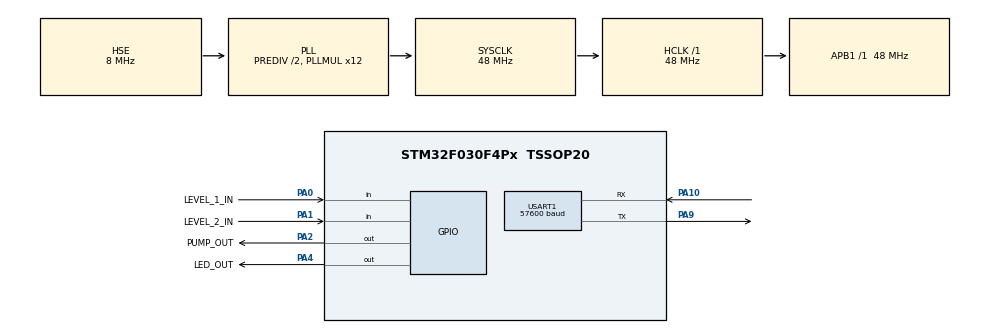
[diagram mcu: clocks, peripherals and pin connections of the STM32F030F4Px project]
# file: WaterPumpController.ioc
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Mcu.Family=STM32F0
Mcu.Name=STM32F030F4Px
Mcu.Package=TSSOP20
NVIC.TIM14_IRQn=true\:0\:0\:false\:false\:true\:true\:true
PA0.GPIO_Label=LEVEL_1_IN
PA0.Signal=GPIO_Input
PA1.GPIO_Label=LEVEL_2_IN
PA1.Signal=GPIO_Input
PA10.Mode=Asynchronous
PA10.Signal=USART1_RX
PA2.GPIO_Label=PUMP_OUT
PA2.Signal=GPIO_Output
PA4.GPIO_Label=LED_OUT
PA4.Signal=GPIO_Output
PA9.Mode=Asynchronous
PA9.Signal=USART1_TX
PF0-OSC_IN.Mode=HSE-External-Oscillator
PF0-OSC_IN.Signal=RCC_OSC_IN
PF1-OSC_OUT.Mode=HSE-External-Oscillator
PF1-OSC_OUT.Signal=RCC_OSC_OUT
ProjectManager.HeapSize=0x200
ProjectManager.StackSize=0x400
ProjectManager.TargetToolchain=STM32CubeIDE
RCC.AHBFreq_Value=48000000
RCC.APB1Freq_Value=48000000
RCC.APB1TimFreq_Value=48000000
RCC.HCLKFreq_Value=48000000
RCC.PLLDivider=RCC_PREDIV_DIV2
RCC.PLLMUL=RCC_PLL_MUL12
RCC.PLLSourceVirtual=RCC_PLLSOURCE_HSE
RCC.SYSCLKFreq_VALUE=48000000
RCC.SYSCLKSource=RCC_SYSCLKSOURCE_PLLCLK
TIM14.Period=1000
TIM14.Prescaler=480
USART1.BaudRate=57600
USART1.Parity=PARITY_NONE
USART1.VirtualMode-Asynchronous=VM_ASYNC
USART1.WordLength=WORDLENGTH_8B
VP_TIM14_VS_ClockSourceINT.Mode=Enable_Timer
board=custom

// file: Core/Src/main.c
/* USER CODE BEGIN Header */
/**
 ******************************************************************************
 * @file           : main.c
 * @brief          : Main program body
 ******************************************************************************
 * @attention
 *
 * <h2><center>&copy; Copyright (c) 2020 STMicroelectronics.
 * All rights reserved.</center></h2>
 *
 * This software component is licensed by ST under BSD 3-Clause license,
 * the "License"; You may not use this file except in compliance with the
 * License. You may obtain a copy of the License at:
 *                        opensource.org/licenses/BSD-3-Clause
 *
 ******************************************************************************
 */
/* USER CODE END Header */
#include "main.h"

/* USER CODE BEGIN Includes */
#include "../../Application/Application.hpp"
/* USER CODE END Includes */

TIM_HandleTypeDef htim14;

UART_HandleTypeDef huart1;

void SystemClock_Config(void);
static void MX_GPIO_Init(void);
static void MX_USART1_UART_Init(void);
static void MX_TIM14_Init(void);

/* USER CODE BEGIN 0 */
/// Callback registered to be call in case of interrupt. Check the interrupt data
///  and kick the application if timer 14 did trigger the interrupt
/// \param[in] htim handle of the timer inteterrupts
void HAL_TIM_PeriodElapsedCallback(TIM_HandleTypeDef* htim)
{
    if(htim->Instance == TIM14) {
        // HAL_GPIO_TogglePin(GPIOA, GPIO_PIN_4);
        ApplicationTimerInterrupt10ms();
    }
    // HAL_GPIO_TogglePin(GPIOA, GPIO_PIN_4);
}

/* USER CODE END 0 */

int main(void)
{

    /* MCU Configuration--------------------------------------------------------*/

    /* Reset of all peripherals, Initializes the Flash interface and the Systick. */
    HAL_Init();

    /* Configure the system clock */
    SystemClock_Config();

    /* Initialize all configured peripherals */
    MX_GPIO_Init();
    MX_USART1_UART_Init();
    MX_TIM14_Init();
    /* USER CODE BEGIN 2 */

    // Switch off pump & LED as soon as possible
    HAL_GPIO_WritePin(PUMP_OUT_GPIO_Port, PUMP_OUT_Pin, GPIO_PIN_RESET);
    HAL_GPIO_WritePin(LED_OUT_GPIO_Port, LED_OUT_Pin, GPIO_PIN_SET);

    // Initialize BGL
    initializeBackgroundLoop(&huart1);
    HAL_TIM_Base_Start_IT(&htim14);
    /* USER CODE END 2 */

    /* Infinite loop */
    while(1) {

        /* USER CODE BEGIN 3 */
        runBackgroudLoop();
    }
    /* USER CODE END 3 */
}

void SystemClock_Config(void)
{
    RCC_OscInitTypeDef RCC_OscInitStruct = {0};
    RCC_ClkInitTypeDef RCC_ClkInitStruct = {0};
    RCC_PeriphCLKInitTypeDef PeriphClkInit = {0};

    /** Initializes the RCC Oscillators according to the specified parameters
     * in the RCC_OscInitTypeDef structure.
     */
    RCC_OscInitStruct.OscillatorType = RCC_OSCILLATORTYPE_HSE;
    RCC_OscInitStruct.HSEState = RCC_HSE_ON;
    RCC_OscInitStruct.PLL.PLLState = RCC_PLL_ON;
    RCC_OscInitStruct.PLL.PLLSource = RCC_PLLSOURCE_HSE;
    RCC_OscInitStruct.PLL.PLLMUL = RCC_PLL_MUL12;
    RCC_OscInitStruct.PLL.PREDIV = RCC_PREDIV_DIV2;
    if(HAL_RCC_OscConfig(&RCC_OscInitStruct) != HAL_OK) {
        Error_Handler();
    }
    /** Initializes the CPU, AHB and APB buses clocks
     */
    RCC_ClkInitStruct.ClockType = RCC_CLOCKTYPE_HCLK | RCC_CLOCKTYPE_SYSCLK
                                  | RCC_CLOCKTYPE_PCLK1;
    RCC_ClkInitStruct.SYSCLKSource = RCC_SYSCLKSOURCE_PLLCLK;
    RCC_ClkInitStruct.AHBCLKDivider = RCC_SYSCLK_DIV1;
    RCC_ClkInitStruct.APB1CLKDivider = RCC_HCLK_DIV1;

    if(HAL_RCC_ClockConfig(&RCC_ClkInitStruct, FLASH_LATENCY_1) != HAL_OK) {
        Error_Handler();
    }
    PeriphClkInit.PeriphClockSelection = RCC_PERIPHCLK_USART1;
    PeriphClkInit.Usart1ClockSelection = RCC_USART1CLKSOURCE_PCLK1;
    if(HAL_RCCEx_PeriphCLKConfig(&PeriphClkInit) != HAL_OK) {
        Error_Handler();
    }
}

static void MX_TIM14_Init(void)
{

    htim14.Instance = TIM14;
    htim14.Init.Prescaler = 480;
    htim14.Init.CounterMode = TIM_COUNTERMODE_UP;
    htim14.Init.Period = 1000;
    htim14.Init.ClockDivision = TIM_CLOCKDIVISION_DIV1;
    htim14.Init.AutoReloadPreload = TIM_AUTORELOAD_PRELOAD_DISABLE;
    if(HAL_TIM_Base_Init(&htim14) != HAL_OK) {
        Error_Handler();
    }

}

static void MX_USART1_UART_Init(void)
{

    huart1.Instance = USART1;
    huart1.Init.BaudRate = 57600;
    huart1.Init.WordLength = UART_WORDLENGTH_8B;
    huart1.Init.StopBits = UART_STOPBITS_1;
    huart1.Init.Parity = UART_PARITY_NONE;
    huart1.Init.Mode = UART_MODE_TX_RX;
    huart1.Init.HwFlowCtl = UART_HWCONTROL_NONE;
    huart1.Init.OverSampling = UART_OVERSAMPLING_16;
    huart1.Init.OneBitSampling = UART_ONE_BIT_SAMPLE_DISABLE;
    huart1.AdvancedInit.AdvFeatureInit = UART_ADVFEATURE_NO_INIT;
    if(HAL_UART_Init(&huart1) != HAL_OK) {
        Error_Handler();
    }

}

static void MX_GPIO_Init(void)
{
    GPIO_InitTypeDef GPIO_InitStruct = {0};

    /* GPIO Ports Clock Enable */
    __HAL_RCC_GPIOF_CLK_ENABLE();
    __HAL_RCC_GPIOA_CLK_ENABLE();

    /*Configure GPIO pin Output Level */
    HAL_GPIO_WritePin(GPIOA, PUMP_OUT_Pin | LED_OUT_Pin, GPIO_PIN_RESET);

    /*Configure GPIO pins : LEVEL_1_IN_Pin LEVEL_2_IN_Pin */
    GPIO_InitStruct.Pin = LEVEL_1_IN_Pin | LEVEL_2_IN_Pin;
    GPIO_InitStruct.Mode = GPIO_MODE_INPUT;
    GPIO_InitStruct.Pull = GPIO_NOPULL;
    HAL_GPIO_Init(GPIOA, &GPIO_InitStruct);

    /*Configure GPIO pins : PUMP_OUT_Pin LED_OUT_Pin */
    GPIO_InitStruct.Pin = PUMP_OUT_Pin | LED_OUT_Pin;
    GPIO_InitStruct.Mode = GPIO_MODE_OUTPUT_PP;
    GPIO_InitStruct.Pull = GPIO_NOPULL;
    GPIO_InitStruct.Speed = GPIO_SPEED_FREQ_LOW;
    HAL_GPIO_Init(GPIOA, &GPIO_InitStruct);

}

void Error_Handler(void)
{
}

/************************ (C) COPYRIGHT STMicroelectronics *****END OF FILE****/
